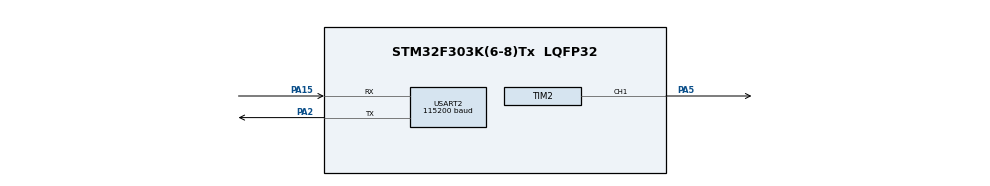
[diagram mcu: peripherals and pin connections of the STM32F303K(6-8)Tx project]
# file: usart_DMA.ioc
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Dma.Request0=USART2_RX
Dma.Request1=USART2_TX
Dma.USART2_RX.0.Direction=DMA_PERIPH_TO_MEMORY
Dma.USART2_RX.0.Instance=DMA1_Channel6
Dma.USART2_RX.0.MemDataAlignment=DMA_MDATAALIGN_BYTE
Dma.USART2_RX.0.MemInc=DMA_MINC_ENABLE
Dma.USART2_RX.0.Mode=DMA_CIRCULAR
Dma.USART2_RX.0.PeriphDataAlignment=DMA_PDATAALIGN_BYTE
Dma.USART2_RX.0.PeriphInc=DMA_PINC_DISABLE
Dma.USART2_RX.0.Priority=DMA_PRIORITY_MEDIUM
Dma.USART2_TX.1.Direction=DMA_MEMORY_TO_PERIPH
Dma.USART2_TX.1.Instance=DMA1_Channel7
Dma.USART2_TX.1.MemDataAlignment=DMA_MDATAALIGN_BYTE
Dma.USART2_TX.1.MemInc=DMA_MINC_ENABLE
Dma.USART2_TX.1.Mode=DMA_CIRCULAR
Dma.USART2_TX.1.PeriphDataAlignment=DMA_PDATAALIGN_BYTE
Dma.USART2_TX.1.PeriphInc=DMA_PINC_DISABLE
Dma.USART2_TX.1.Priority=DMA_PRIORITY_MEDIUM
Mcu.Family=STM32F3
Mcu.Name=STM32F303K(6-8)Tx
Mcu.Package=LQFP32
NVIC.DMA1_Channel6_IRQn=true\:0\:0\:false\:false\:true\:false\:true
NVIC.DMA1_Channel7_IRQn=true\:0\:0\:false\:false\:true\:false\:true
NVIC.PriorityGroup=NVIC_PRIORITYGROUP_4
NVIC.TIM2_IRQn=true\:0\:0\:false\:false\:true\:true\:true
PA15.Mode=Asynchronous
PA15.Signal=USART2_RX
PA2.Mode=Asynchronous
PA2.Signal=USART2_TX
PA5.Signal=S_TIM2_CH1_ETR
ProjectManager.HeapSize=0x200
ProjectManager.StackSize=0x400
ProjectManager.TargetToolchain=STM32CubeIDE
RCC.AHBFreq_Value=8000000
RCC.APB1Freq_Value=8000000
RCC.APB2Freq_Value=8000000
RCC.CortexFreq_Value=8000000
RCC.HSE_VALUE=8000000
RCC.HSI_VALUE=8000000
RCC.SYSCLKFreq_VALUE=8000000
SH.S_TIM2_CH1_ETR.0=TIM2_CH1,PWM Generation1 CH1
TIM2.Channel-PWM\ Generation1\ CH1=TIM_CHANNEL_1
USART2.BaudRate=115200
USART2.VirtualMode-Asynchronous=VM_ASYNC
VP_TIM2_VS_ClockSourceINT.Mode=Internal
board=custom

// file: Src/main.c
/* USER CODE BEGIN Header */
/**
 ******************************************************************************
 * @file           : main.c
 * @brief          : Main program body
 ******************************************************************************
 * @attention
 *
 * <h2><center>&copy; Copyright (c) 2019 STMicroelectronics.
 * All rights reserved.</center></h2>
 *
 * This software component is licensed by ST under BSD 3-Clause license,
 * the "License"; You may not use this file except in compliance with the
 * License. You may obtain a copy of the License at:
 *                        opensource.org/licenses/BSD-3-Clause
 *
 ******************************************************************************
 */
/* USER CODE END Header */

#include "main.h"
#include "dma.h"
#include "usart.h"
#include "gpio.h"
#include "stdbool.h"

enum modes {MANUAL,AUTO};
enum states {RECEIVING,IGNORING};
enum count {UP,DOWN};
enum modes mode = AUTO;
bool change = false;

/* USER CODE BEGIN PV */
uint8_t tx_data[] = "Data to send over UART DMA!\n\r";
uint8_t rx_data[10];
uint16_t  PWM = 0;

/* USER CODE END PV */

void SystemClock_Config(void);
/* USER CODE BEGIN PFP */
void receive_dma_data(const uint8_t* data, uint16_t len);
void setDutyCycle(uint8_t D);
void fadeInOut();
/* USER CODE END PFP */

int main(void)
{

	/* MCU Configuration--------------------------------------------------------*/

	/* Reset of all peripherals, Initializes the Flash interface and the Systick. */

	LL_APB2_GRP1_EnableClock(LL_APB2_GRP1_PERIPH_SYSCFG);
	LL_APB1_GRP1_EnableClock(LL_APB1_GRP1_PERIPH_PWR);

	NVIC_SetPriorityGrouping(NVIC_PRIORITYGROUP_4);

	/* System interrupt init*/

	/* Configure the system clock */
	SystemClock_Config();

	/* Initialize all configured peripherals */
	MX_GPIO_Init();
	MX_DMA_Init();
	MX_USART2_UART_Init();
	MX_TIM2_Init();
	/* USER CODE BEGIN 2 */
	USART2_RegisterCallback(receive_dma_data);
	LL_TIM_CC_EnableChannel(TIM2, LL_TIM_CHANNEL_CH1);
	LL_TIM_EnableCounter(TIM2);

	/* USER CODE END 2 */

	/* Infinite loop */
	while (1)
	{

		USART2_CheckDmaReception();
		LL_mDelay(10);

		if(mode == MANUAL){

			if(change)
				LL_TIM_OC_SetCompareCH1(TIM2, 0);

			setPWM(PWM);
		}else
		{

			fadeInOut();

		}

	}
}

void SystemClock_Config(void)
{
	LL_FLASH_SetLatency(LL_FLASH_LATENCY_0);

	if(LL_FLASH_GetLatency() != LL_FLASH_LATENCY_0)
	{
		Error_Handler();
	}
	LL_RCC_HSI_Enable();

	/* Wait till HSI is ready */
	while(LL_RCC_HSI_IsReady() != 1)
	{

	}
	LL_RCC_HSI_SetCalibTrimming(16);
	LL_RCC_SetAHBPrescaler(LL_RCC_SYSCLK_DIV_1);
	LL_RCC_SetAPB1Prescaler(LL_RCC_APB1_DIV_1);
	LL_RCC_SetAPB2Prescaler(LL_RCC_APB1_DIV_1);
	LL_RCC_SetSysClkSource(LL_RCC_SYS_CLKSOURCE_HSI);

	/* Wait till System clock is ready */
	while(LL_RCC_GetSysClkSource() != LL_RCC_SYS_CLKSOURCE_STATUS_HSI)
	{

	}
	LL_Init1msTick(8000000);
	LL_SYSTICK_SetClkSource(LL_SYSTICK_CLKSOURCE_HCLK);
	LL_SetSystemCoreClock(8000000);
}

/* USER CODE BEGIN 4 */
void setDutyCycle(uint8_t D){

	uint8_t pulse_length = (LL_TIM_GetAutoReload(TIM2)* D) / 100;
	LL_TIM_OC_SetCompareCH1(TIM2, pulse_length);

}

void setPWM(uint8_t pwm){

	static uint8_t old_PWM = 0;

	if(change == true)
		old_PWM = 0;

	if(old_PWM<pwm){

		for(int i = 1; i<=pwm-old_PWM;i++){

			setDutyCycle(old_PWM+i);
			LL_mDelay(10);
		}

	}else if(old_PWM>pwm){

		for(int i = 1; i<=old_PWM-pwm;i++){

			setDutyCycle(old_PWM-i);
			LL_mDelay(10);
		}

	} else if(old_PWM==pwm){

	}

	change=false;
	old_PWM=pwm;
}

void fadeInOut(){

	static enum count counting = UP;
	static uint8_t old_PWM = 0;

	if(counting == UP && old_PWM == 100){
		counting = DOWN;
	} else 	if(counting == DOWN && old_PWM == 0){
		counting = UP;
	}

	if(counting == UP){
		old_PWM += 1;
		setDutyCycle(old_PWM);
	} else 	if(counting == DOWN){
		old_PWM -= 1;
		setDutyCycle(old_PWM);
	}

}

uint8_t process_pwm_data(uint8_t sign_1,uint8_t sign_2){

	char myarray[2] = {sign_1,sign_2};
	int pwm;
	sscanf(myarray, "%d", &pwm);

	return pwm;

}

void receive_dma_data(const uint8_t* data, uint16_t len)
{

	static enum states state = IGNORING;
	static uint16_t PWM_info[6];
	static uint16_t PWM_array_position = 0;

	for(uint8_t i = 0; i < len; i++)
	{

		if(mode == MANUAL){

			if(*(data+i) == '$' && state == IGNORING)
			{

				state=RECEIVING;
			} else if(state == RECEIVING && PWM_array_position<5){

				PWM_info[PWM_array_position++]=*(data+i);

			}

			else if(state == RECEIVING && PWM_array_position==5 && *(data+i) == '$' ){

				PWM_array_position = 0;
				state = IGNORING;
				PWM = process_pwm_data(PWM_info[3],PWM_info[4]);

			} else if(state == RECEIVING && PWM_array_position>4 ){

				PWM_array_position = 0;
				state = IGNORING;
			}

			if(state == RECEIVING && PWM_info[0] == 'a' && PWM_info[1] == 'u' && PWM_info[2] == 't' && PWM_info[3] == 'o' && PWM_info[4] == '$'){

				mode = AUTO;
				PWM_array_position = 0;
				state = IGNORING;

			}
		} else
		{

			if(*(data+i) == '$' && state == IGNORING)
			{
				state=RECEIVING;
			} else if(state == RECEIVING && PWM_array_position<6){

				PWM_info[PWM_array_position++]=*(data+i);

			}

			else if(state == RECEIVING && PWM_info[0] == 'm' && PWM_info[1] == 'a' && PWM_info[2] == 'n' && PWM_info[3] == 'u' && PWM_info[4] == 'a' && PWM_info[5] == 'l'&& *(data+i) == '$' ){

				PWM_array_position = 0;
				state = IGNORING;
				mode = MANUAL;;
				change = true; //zmena stavu z auto na manual, sluzi ako pomocna premena na prepis starej hodnoty PWM na 0

			} else if(state == RECEIVING && PWM_array_position>5 ){

				PWM_array_position = 0;
				state = IGNORING;
			}

		}
	}
}
/* USER CODE END 4 */

void Error_Handler(void)
{
}

/************************ (C) COPYRIGHT STMicroelectronics *****END OF FILE****/
